# PIC32CM5112SG00064 device description
Architecture: CORTEX-M23; Family: PIC32CM; Series: PIC32CMSG00
Registers are 32-bit, read-write, reset 0x0 unless marked. A register's access mark holds for its fields unless they carry their own. Offsets are from the block's base; [hi:lo] are bit positions; {n}, {i} and the like mark numbered series; 'fields as' and 'values as' point back to an identical list.

## OSC32KCTRL — 32kHz Oscillators Control
Instances: OSC32KCTRL 0x45008000
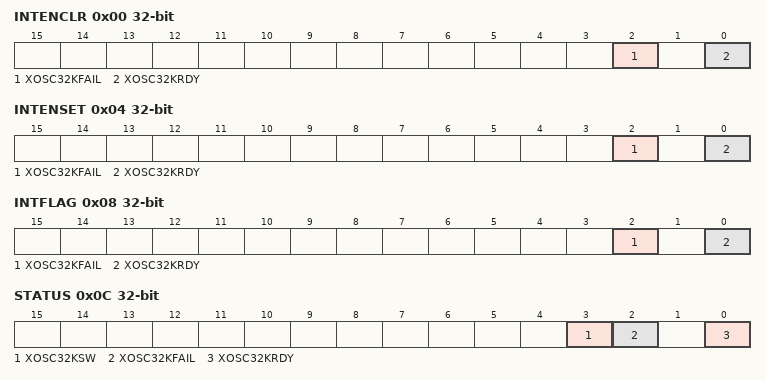
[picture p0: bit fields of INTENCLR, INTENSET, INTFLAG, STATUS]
0x00 INTENCLR (atomic clear) — Interrupt Enable Clear
  [2] XOSC32KFAIL — XOSC32K Clock Failure Detector Interrupt Enable
  [0] XOSC32KRDY — XOSC32K Ready Interrupt Enable
0x04 INTENSET (atomic set) — Interrupt Enable Set
  fields as INTENCLR
0x08 INTFLAG (atomic clear) — Interrupt Flag Status and Clear
  [2] XOSC32KFAIL — XOSC32K Clock Failure Detector
  [0] XOSC32KRDY — XOSC32K Ready
0x0C STATUS ro — Power and Clocks Status
  [3] XOSC32KSW — XOSC32K Clock switch
  [2] XOSC32KFAIL — XOSC32K Clock Failure Detector
  [0] XOSC32KRDY — XOSC32K Ready
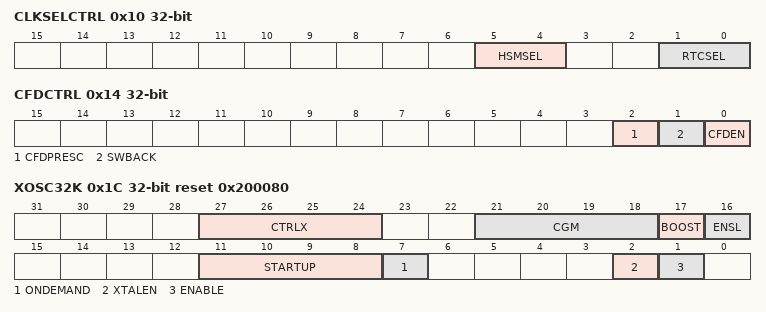
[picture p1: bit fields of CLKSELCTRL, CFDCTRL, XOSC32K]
0x10 CLKSELCTRL — Clock Selection Control
  [5:4] HSMSEL — HSM Clock Selection
    0=ULP32K (32.768kHz from 32kHz internal ULP oscillator); 2=XOSC32K (32.768kHz from 32.768kHz external crystal oscillator)
  [1:0] RTCSEL — RTC Clock Selection
    0=ULP32K (32.768kHz from 32kHz internal ULP oscillator); 1=ULP1K (1.024kHz from 32kHz internal ULP oscillator); 2=XOSC32K (32.768kHz from 32.768kHz external crystal oscillator); 3=XOSC1K (1.024kHz from 32.768kHz internal oscillator)
0x14 CFDCTRL — Clock Failure Detector Control
  [2] CFDPRESC — Clock Failure Detector Prescaler
  [1] SWBACK — Clock Switch Back
  [0] CFDEN — Clock Failure Detector Enable
0x18 EVCTRL — Event Control
  [0] CFDEO — Clock Failure Detector Event Output Enable
0x1C XOSC32K reset 0x200080 — 32kHz External Crystal Oscillator (XOSC32K) Control
  [27:24] CTRLX — Extended Control
  [21:18] CGM — Control Gain Mode
    0=The lower Control Gain Mode value; {v}=A higher Control Gain Mode value than CGM{v-1} (v=1..14); 15=The highest Control Gain Mode value
  [17] BOOST — Gain Boost
  [16] ENSL — Enable Servo Loop
  [11:8] STARTUP — Startup Mode
    0=1CYCLE (1 ULP clock cycle); 1=16CYCLES (16 ULP clock cycles); 2=32CYCLES (32 ULP clock cycles); 3=2048CYCLES (2048 ULP clock cycles); 4=4096CYCLES (4096 ULP clock cycles); 5=8192CYCLES (8192 ULP clock cycles); 6=16384CYCLES (16384 ULP clock cycles); 7=32768CYCLES (32768 ULP clock cycles); 8=65536CYCLES (65536 ULP clock cycles); 9=131072CYCLES (131072 ULP clock cycles); 10=262144CYCLES (262144 ULP clock cycles)
  [7] ONDEMAND — On Demand Mode
  [2] XTALEN — Crystal Oscillator Enable
  [1] ENABLE — Oscillator Enable

## PAC — Peripheral Access Controller
Instances: PAC 0x44022000
0x00 CTRLA — Control A Register
  [2] PRIV — Privileged Access Only
    0=DISABLE (Macro register accessible in privileged and unprivileged accesses.); 1=ENABLE (Macro registers only accessible in privileged accesses)
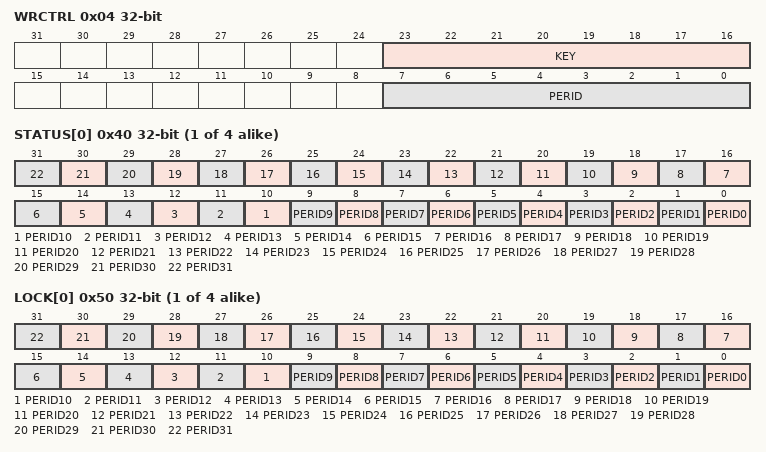
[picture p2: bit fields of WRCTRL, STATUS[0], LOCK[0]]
0x04 WRCTRL wo — Write Control Register
  [23:16] KEY — Peripheral Access Control Key
    0=OFF (OFF - No Action); 1=CLEAR (CLEAR - Clear the peripheral write protection); 2=SET (SET - Set the peripheral write protection); 3=LOCK (LOCK - Set and Lock the write protection state of the peripheral until the next reset)
  [7:0] PERID — Peripheral Identifier
{0x40+4i} STATUS[{i}] (i=0..3) ro — Peripheral Status n Register
  [all] fields
    0=Write Protection disabled; 1=Write Protection enabled
  [n] PERID{n} (n=0..31) — PERID Write Protection Status
{0x50+4i} LOCK[{i}] (i=0..3) ro — Peripheral Lock n Register
  [all] fields
    0=Write Protection Unlocked; 1=Write Protection Locked
  [n] PERID{n} (n=0..31) — PERID Write Protection Lock Status

## PM — Power Manager
Instances: PM 0x45000000
0x00 CTRLA 8-bit — Control A
  [2] IORET — I/O Retention
    0=NOIORET (When the device exits the HIBERNATE or BACKUP mode, the I/O line configuration are released.); 1=IORET (When the device exits the HIBERNATE or BACKUP mode, the I/O line configuration are stretched.)
0x01 SLEEPCFG 8-bit reset 0x2 — Sleep Configuration
  [2:0] SLEEPMODE
    2=IDLE (CPU, AHB and APB clocks are OFF); 4=STANDBY (All Clocks are OFF); 5=HIBERNATE (Backup domain is ON as well as some PDRAMs); 6=BACKUP (Only Backup domain is powered ON); 7=OFF (All power domains are powered OFF)
0x04 INTENCLR 8-bit (atomic clear) — Interrupt Enable Clear
  [0] SLEEPRDY — Backup Sleep Mode Entry Ready Enable
0x05 INTENSET 8-bit (atomic set) — Interrupt Enable Set
  [0] SLEEPRDY — Backup Sleep Mode Entry Ready Enable
0x06 INTFLAG 8-bit (atomic clear) — Interrupt Flag Status and Clear
  [0] SLEEPRDY — Backup Sleep Mode Entry Ready
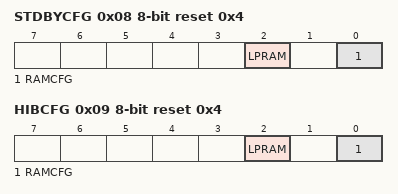
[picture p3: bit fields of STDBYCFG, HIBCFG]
0x08 STDBYCFG 8-bit reset 0x4 — Standby Configuration
  [2] LPRAM — Low Power RAM Enable
  [0] RAMCFG — Ram Configuration
    0=RET (All the RAMs are retained); 1=OFF (Only the first 32K bytes are retained)
0x09 HIBCFG 8-bit reset 0x4 — Hibernate Configuration
  fields as STDBYCFG
